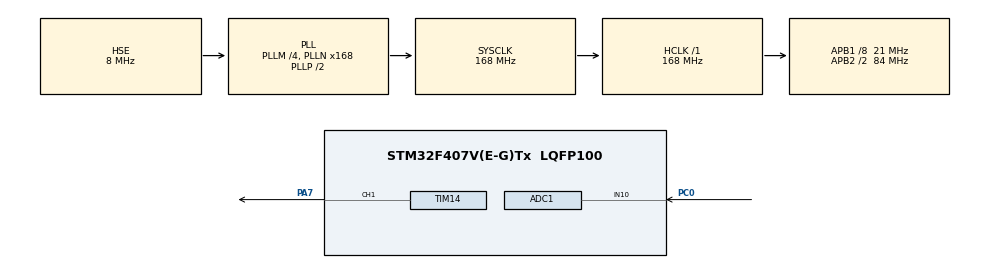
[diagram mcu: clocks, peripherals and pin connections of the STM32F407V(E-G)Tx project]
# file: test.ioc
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ADC1.Channel-4\#ChannelRegularConversion=ADC_CHANNEL_10
ADC1.NbrOfConversionFlag=1
ADC1.Rank-4\#ChannelRegularConversion=1
ADC1.SamplingTime-4\#ChannelRegularConversion=ADC_SAMPLETIME_3CYCLES
ADC1.master=1
Mcu.Family=STM32F4
Mcu.Name=STM32F407V(E-G)Tx
Mcu.Package=LQFP100
NVIC.PriorityGroup=NVIC_PRIORITYGROUP_4
NVIC.TIM8_TRG_COM_TIM14_IRQn=true\:0\:0\:false\:false\:true\:true
PA7.Signal=S_TIM14_CH1
PC0.Signal=ADCx_IN10
PH0-OSC_IN.Mode=HSE-External-Oscillator
PH0-OSC_IN.Signal=RCC_OSC_IN
PH1-OSC_OUT.Mode=HSE-External-Oscillator
PH1-OSC_OUT.Signal=RCC_OSC_OUT
ProjectManager.HeapSize=0x200
ProjectManager.StackSize=0x400
ProjectManager.TargetToolchain=EWARM
RCC.48MHZClocksFreq_Value=84000000
RCC.AHBFreq_Value=168000000
RCC.APB1CLKDivider=RCC_HCLK_DIV8
RCC.APB1Freq_Value=21000000
RCC.APB1TimFreq_Value=42000000
RCC.APB2CLKDivider=RCC_HCLK_DIV2
RCC.APB2Freq_Value=84000000
RCC.APB2TimFreq_Value=168000000
RCC.CortexFreq_Value=168000000
RCC.HCLKFreq_Value=168000000
RCC.HSE_VALUE=8000000
RCC.HSI_VALUE=16000000
RCC.LSE_VALUE=32768
RCC.PLLM=4
RCC.PLLN=168
RCC.PLLSourceVirtual=RCC_PLLSOURCE_HSE
RCC.SYSCLKFreq_VALUE=168000000
RCC.SYSCLKSource=RCC_SYSCLKSOURCE_PLLCLK
RCC.VCOOutputFreq_Value=336000000
SH.ADCx_IN10.0=ADC1_IN10,IN10
SH.S_TIM14_CH1.0=TIM14_CH1,Output Compare1 CH1
TIM14.Channel=TIM_CHANNEL_1
TIM14.Prescaler=840
VP_TIM14_VS_ClockSourceINT.Mode=Enable_Timer
board=test

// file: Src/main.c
#include "main.h"
#include "stm32f4xx_hal.h"

/* USER CODE BEGIN Includes */
#include <stdio.h>
/* USER CODE END Includes */

ADC_HandleTypeDef hadc1;

TIM_HandleTypeDef htim14;

/* USER CODE BEGIN PV */
/* Private variables ---------------------------------------------------------*/
int result = 0;
uint32_t i = 0;
/* USER CODE END PV */

void SystemClock_Config(void);
static void MX_GPIO_Init(void);
static void MX_ADC1_Init(void);
static void MX_TIM14_Init(void);

void HAL_TIM_MspPostInit(TIM_HandleTypeDef *htim);

/* USER CODE BEGIN PFP */
/* Private function prototypes -----------------------------------------------*/

/* USER CODE END PFP */

/* USER CODE BEGIN 0 */
#define SERVO_180 8200
#define SERVO_0 1800

void set_pos(uint8_t pos)
{
  uint32_t tmp = (SERVO_180 - SERVO_0)/ 180;
  TIM14->CCR1 = SERVO_0 + tmp * pos;
}
/* USER CODE END 0 */

int main(void)
{

  /* MCU Configuration----------------------------------------------------------*/

  /* Reset of all peripherals, Initializes the Flash interface and the Systick. */
  HAL_Init();

  /* Configure the system clock */
  SystemClock_Config();

  /* Initialize all configured peripherals */
  MX_GPIO_Init();
  MX_ADC1_Init();
  MX_TIM14_Init();
  /* USER CODE BEGIN 2 */
  //TIM14->CR1 |= TIM_CR1_CEN;
  /* USER CODE END 2 */

  /* Infinite loop */
  /* USER CODE BEGIN WHILE */
  while (1)
  {
    HAL_ADC_Start(&hadc1);
    HAL_ADC_PollForConversion(&hadc1, HAL_MAX_DELAY);
    result = HAL_ADC_GetValue(&hadc1);
    printf("%i\n", result);
    HAL_Delay(100);
    i = 4000 - result ;
    i = 180 * i / 1000;
    //set_pos(i);
  /* USER CODE END WHILE */

  /* USER CODE BEGIN 3 */

    HAL_ADC_Stop(&hadc1);
  }
  /* USER CODE END 3 */

}

void SystemClock_Config(void)
{

  RCC_OscInitTypeDef RCC_OscInitStruct;
  RCC_ClkInitTypeDef RCC_ClkInitStruct;

    /**Configure the main internal regulator output voltage
    */
  __HAL_RCC_PWR_CLK_ENABLE();

  __HAL_PWR_VOLTAGESCALING_CONFIG(PWR_REGULATOR_VOLTAGE_SCALE1);

    /**Initializes the CPU, AHB and APB busses clocks
    */
  RCC_OscInitStruct.OscillatorType = RCC_OSCILLATORTYPE_HSE;
  RCC_OscInitStruct.HSEState = RCC_HSE_ON;
  RCC_OscInitStruct.PLL.PLLState = RCC_PLL_ON;
  RCC_OscInitStruct.PLL.PLLSource = RCC_PLLSOURCE_HSE;
  RCC_OscInitStruct.PLL.PLLM = 4;
  RCC_OscInitStruct.PLL.PLLN = 168;
  RCC_OscInitStruct.PLL.PLLP = RCC_PLLP_DIV2;
  RCC_OscInitStruct.PLL.PLLQ = 4;
  if (HAL_RCC_OscConfig(&RCC_OscInitStruct) != HAL_OK)
  {
    _Error_Handler(__FILE__, __LINE__);
  }

    /**Initializes the CPU, AHB and APB busses clocks
    */
  RCC_ClkInitStruct.ClockType = RCC_CLOCKTYPE_HCLK|RCC_CLOCKTYPE_SYSCLK
                              |RCC_CLOCKTYPE_PCLK1|RCC_CLOCKTYPE_PCLK2;
  RCC_ClkInitStruct.SYSCLKSource = RCC_SYSCLKSOURCE_PLLCLK;
  RCC_ClkInitStruct.AHBCLKDivider = RCC_SYSCLK_DIV1;
  RCC_ClkInitStruct.APB1CLKDivider = RCC_HCLK_DIV8;
  RCC_ClkInitStruct.APB2CLKDivider = RCC_HCLK_DIV2;

  if (HAL_RCC_ClockConfig(&RCC_ClkInitStruct, FLASH_LATENCY_5) != HAL_OK)
  {
    _Error_Handler(__FILE__, __LINE__);
  }

    /**Configure the Systick interrupt time
    */
  HAL_SYSTICK_Config(HAL_RCC_GetHCLKFreq()/1000);

    /**Configure the Systick
    */
  HAL_SYSTICK_CLKSourceConfig(SYSTICK_CLKSOURCE_HCLK);

  /* SysTick_IRQn interrupt configuration */
  HAL_NVIC_SetPriority(SysTick_IRQn, 0, 0);
}

/* ADC1 init function */
static void MX_ADC1_Init(void)
{

  ADC_ChannelConfTypeDef sConfig;

    /**Configure the global features of the ADC (Clock, Resolution, Data Alignment and number of conversion)
    */
  hadc1.Instance = ADC1;
  hadc1.Init.ClockPrescaler = ADC_CLOCK_SYNC_PCLK_DIV4;
  hadc1.Init.Resolution = ADC_RESOLUTION_12B;
  hadc1.Init.ScanConvMode = DISABLE;
  hadc1.Init.ContinuousConvMode = DISABLE;
  hadc1.Init.DiscontinuousConvMode = DISABLE;
  hadc1.Init.ExternalTrigConvEdge = ADC_EXTERNALTRIGCONVEDGE_NONE;
  hadc1.Init.ExternalTrigConv = ADC_SOFTWARE_START;
  hadc1.Init.DataAlign = ADC_DATAALIGN_RIGHT;
  hadc1.Init.NbrOfConversion = 1;
  hadc1.Init.DMAContinuousRequests = DISABLE;
  hadc1.Init.EOCSelection = ADC_EOC_SINGLE_CONV;
  if (HAL_ADC_Init(&hadc1) != HAL_OK)
  {
    _Error_Handler(__FILE__, __LINE__);
  }

    /**Configure for the selected ADC regular channel its corresponding rank in the sequencer and its sample time.
    */
  sConfig.Channel = ADC_CHANNEL_10;
  sConfig.Rank = 1;
  sConfig.SamplingTime = ADC_SAMPLETIME_3CYCLES;
  if (HAL_ADC_ConfigChannel(&hadc1, &sConfig) != HAL_OK)
  {
    _Error_Handler(__FILE__, __LINE__);
  }

}

/* TIM14 init function */
static void MX_TIM14_Init(void)
{

  TIM_OC_InitTypeDef sConfigOC;

  htim14.Instance = TIM14;
  htim14.Init.Prescaler = 840;
  htim14.Init.CounterMode = TIM_COUNTERMODE_UP;
  htim14.Init.Period = 0;
  htim14.Init.ClockDivision = TIM_CLOCKDIVISION_DIV1;
  if (HAL_TIM_Base_Init(&htim14) != HAL_OK)
  {
    _Error_Handler(__FILE__, __LINE__);
  }

  if (HAL_TIM_OC_Init(&htim14) != HAL_OK)
  {
    _Error_Handler(__FILE__, __LINE__);
  }

  sConfigOC.OCMode = TIM_OCMODE_TIMING;
  sConfigOC.Pulse = 0;
  sConfigOC.OCPolarity = TIM_OCPOLARITY_HIGH;
  sConfigOC.OCFastMode = TIM_OCFAST_DISABLE;
  if (HAL_TIM_OC_ConfigChannel(&htim14, &sConfigOC, TIM_CHANNEL_1) != HAL_OK)
  {
    _Error_Handler(__FILE__, __LINE__);
  }

  HAL_TIM_MspPostInit(&htim14);

}

/** Configure pins as
        * Analog
        * Input
        * Output
        * EVENT_OUT
        * EXTI
*/
static void MX_GPIO_Init(void)
{

  /* GPIO Ports Clock Enable */
  __HAL_RCC_GPIOH_CLK_ENABLE();
  __HAL_RCC_GPIOC_CLK_ENABLE();
  __HAL_RCC_GPIOA_CLK_ENABLE();

}

void _Error_Handler(char *file, int line)
{
  while(1)
  {
  }
}

/************************ (C) COPYRIGHT STMicroelectronics *****END OF FILE****/
